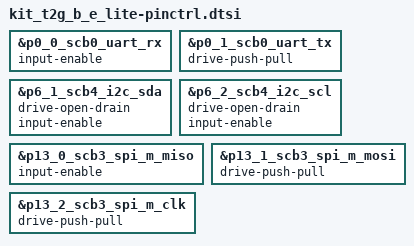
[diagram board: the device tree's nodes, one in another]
/*
 * Copyright (c) 2026 Infineon Technologies AG
 * SPDX-License-Identifier: Apache-2.0
 */

#include <infineon/cat1a/cyt2bl/cyt2bl.100-lqfp.dtsi>

&p0_0_scb0_uart_rx {
	input-enable;
};

&p0_1_scb0_uart_tx {
	drive-push-pull;
};

&p6_1_scb4_i2c_sda {
	drive-open-drain;
	input-enable;
};

&p6_2_scb4_i2c_scl {
	drive-open-drain;
	input-enable;
};

&p13_0_scb3_spi_m_miso {
		input-enable;
	};

&p13_1_scb3_spi_m_mosi {
		drive-push-pull;
	};

&p13_2_scb3_spi_m_clk {
		drive-push-pull;
	 };


